# XMC4500 register map
Vendor: Infineon; File version: 1.5.3 (Reference Manual v1.5)
CPU: CM4 r2p0, little endian, MPU, FPU, 6 interrupt priority bits
Registers are 32-bit, read-write, reset 0x0 unless marked. A register's access mark holds for its fields unless they carry their own. Offsets are from the block's base; [hi:lo] are bit positions; 'fields as' and 'values as' point back to an identical list.

## SCU_OSC — System Control Unit
Base 0x50004700
0x00 OSCHPSTAT ro — OSC_HP Status Register
  [0] X1D — XTAL1 Data Value
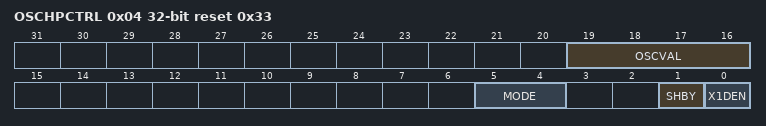
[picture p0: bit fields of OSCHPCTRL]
0x04 OSCHPCTRL reset 0x33 — OSC_HP Control Register
  [19:16] OSCVAL — OSC Frequency Value
  [5:4] MODE — Oscillator Mode
    0=External Crystal Mode and External Input Clock Mode. The oscillator Power-Saving Mode is not entered.; 1=OSC is disabled. The oscillator Power-Saving Mode is not entered.; 2=External Input Clock Mode and the oscillator Power-Saving Mode is entered; 3=OSC is disabled. The oscillator Power-Saving Mode is entered.
  [1] SHBY — Shaper Bypass
    0=The shaper is not bypassed; 1=The shaper is bypassed
  [0] X1DEN — XTAL1 Data Enable
    0=Bit X1D is not updated; 1=Bit X1D can be updated
0x0C CLKCALCONST — Clock Calibration Constant Register
  [3:0] CALIBCONST — Clock Calibration Constant Value

## SCU_TRAP — System Control Unit
Base 0x50004160
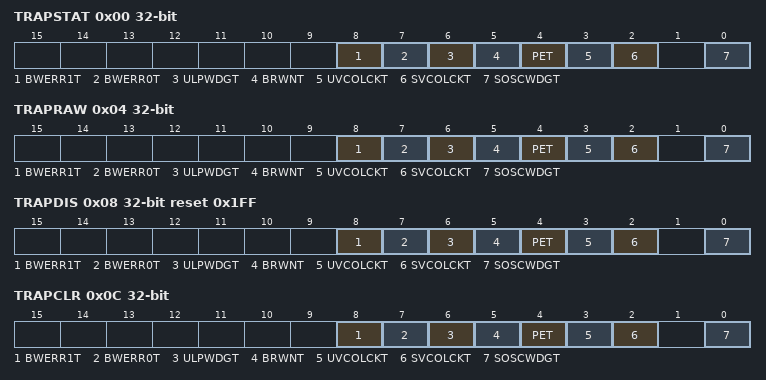
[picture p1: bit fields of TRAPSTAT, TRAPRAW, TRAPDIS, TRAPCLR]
0x00 TRAPSTAT ro — Trap Status Register
  [all] fields
    0=No pending trap request; 1=Pending trap request
  [8] BWERR1T — Peripheral Bridge 1 Trap Status
  [7] BWERR0T — Peripheral Bridge 0 Trap Status
  [6] ULPWDGT — OSC_ULP Oscillator Watchdog Trap Status
  [5] BRWNT — Brown Out Trap Status
  [4] PET — Parity Error Trap Status
  [3] UVCOLCKT — USB VCO Lock Trap Status
  [2] SVCOLCKT — System VCO Lock Trap Status
  [0] SOSCWDGT — OSC_HP Oscillator Watchdog Trap Status
0x04 TRAPRAW ro — Trap Raw Status Register
  [all] fields
    0=No pending trap request; 1=Pending trap request
  [8] BWERR1T — Peripheral Bridge 1 Trap Raw Status
  [7] BWERR0T — Peripheral Bridge 0 Trap Raw Status
  [6] ULPWDGT — OSC_ULP Oscillator Watchdog Trap Raw Status
  [5] BRWNT — Brown Out Trap Raw Status
  [4] PET — Parity Error Trap Raw Status
  [3] UVCOLCKT — USB VCO Lock Trap Raw Status
  [2] SVCOLCKT — System VCO Lock Trap Raw Status
  [0] SOSCWDGT — OSC_HP Oscillator Watchdog Trap Raw Status
0x08 TRAPDIS reset 0x1FF — Trap Disable Register
  [all] fields
    0=Trap request enabled; 1=Trap request disabled
  [8] BWERR1T — Peripheral Bridge 1 Trap Disable
  [7] BWERR0T — Peripheral Bridge 0 Trap Disable
  [6] ULPWDGT — OSC_ULP Oscillator Watchdog Trap Disable
  [5] BRWNT — Brown Out Trap Disable
  [4] PET — Parity Error Trap Disable
  [3] UVCOLCKT — USB VCO Lock Trap Disable
  [2] SVCOLCKT — System VCO Lock Trap Disable
  [0] SOSCWDGT — OSC_HP Oscillator Watchdog Trap Disable
0x0C TRAPCLR wo — Trap Clear Register
  [all] fields
    0=No effect; 1=Clear trap request
  [8] BWERR1T — Peripheral Bridge 1 Trap Clear
  [7] BWERR0T — Peripheral Bridge 0 Trap Clear
  [6] ULPWDGT — OSC_ULP Oscillator Watchdog Trap Clear
  [5] BRWNT — Brown Out Trap Clear
  [4] PET — Parity Error Trap Clear
  [3] UVCOLCKT — USB VCO Lock Trap Clear
  [2] SVCOLCKT — System VCO Lock Trap Clear
  [0] SOSCWDGT — OSC_HP Oscillator Watchdog Trap Clear
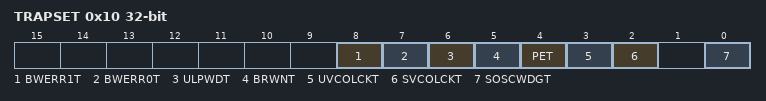
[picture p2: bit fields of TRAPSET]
0x10 TRAPSET wo
  [all] fields
    0=No effect; 1=Set trap request
  [8] BWERR1T — Peripheral Bridge 1 Trap Set
  [7] BWERR0T — Peripheral Bridge 0 Trap Set
  [6] ULPWDT — OSC_ULP Oscillator Watchdog Trap Set
  [5] BRWNT — Brown Out Trap Set
  [4] PET — Parity Error Trap Set
  [3] UVCOLCKT — USB VCO Lock Trap Set
  [2] SVCOLCKT — System VCO Lock Trap Set
  [0] SOSCWDGT — OSC_HP Oscillator Watchdog Trap Set

## SCU_HIBERNATE — System Control Unit
Base 0x50004300
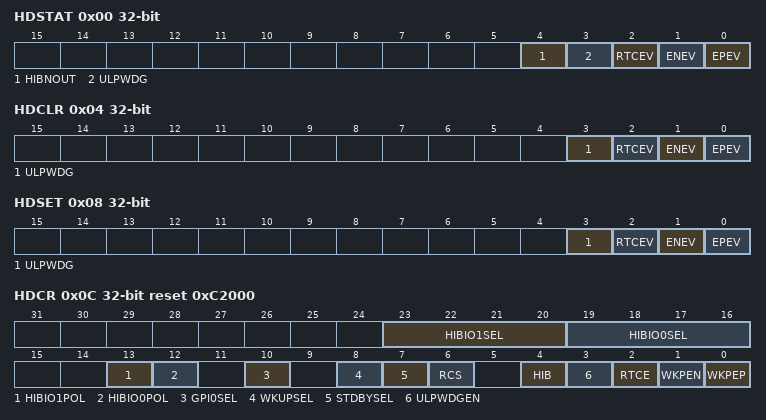
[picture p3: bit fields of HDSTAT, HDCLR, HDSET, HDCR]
0x00 HDSTAT ro — Hibernate Domain Status Register
  [4] HIBNOUT — Hibernate Control Status
    0=Hibernate not driven active to pads; 1=Hibernate driven active to pads
  [3] ULPWDG — ULP WDG Alarm Status
    0=Watchdog alarm did not occur; 1=Watchdog alarm occurred
  [2] RTCEV — RTC Event
    0=Wake-up on RTC event inactive; 1=Wake-up on RTC event active
  [1] ENEV — Wake-up Pin Event Negative Edge
    0=Wake-up on negative edge pin event inactive; 1=Wake-up on negative edge pin event active
  [0] EPEV — Wake-up Pin Event Positive Edge
    0=Wake-up on positive edge pin event inactive; 1=Wake-up on positive edge pin event active
0x04 HDCLR wo — Hibernate Domain Status Clear Register
  [3] ULPWDG — ULP WDG Alarm Clear
    0=No effect; 1=Clear watchdog alarm
  [2] RTCEV — RTC Event Clear
    0=No effect; 1=Clear wake-up event
  [1] ENEV — Wake-up Pin Event Negative Edge Clear
    0=No effect; 1=Clear wake-up event
  [0] EPEV — Wake-up Pin Event Positive Edge Clear
    0=No effect; 1=Clear wake-up event
0x08 HDSET wo — Hibernate Domain Status Set Register
  [3] ULPWDG — ULP WDG Alarm Set
    0=No effect; 1=Set watchdog alarm
  [2] RTCEV — RTC Event Set
    0=No effect; 1=Set wake-up event
  [1] ENEV — Wake-up Pin Event Negative Edge Set
    0=No effect; 1=Set wake-up event
  [0] EPEV — Wake-up Pin Event Positive Edge Set
    0=No effect; 1=Set wake-up event
0x0C HDCR reset 0xC2000 — Hibernate Domain Control Register
  [23:20] HIBIO1SEL — HIB_IO_1 Pin I/O Control (Default WKUP)
    0=Direct input, No input pull device connected; 1=Direct input, Input pull-down device connected; 2=Direct input, Input pull-up device connected; 8=Push-pull HIB Control output; 9=Push-pull WDT service output; 10=Push-pull GPIO output; 12=Open-drain HIB Control output; 13=Open-drain WDT service output; 14=Open-drain GPIO output
  [19:16] HIBIO0SEL — HIB_IO_0 Pin I/O Control (default HIBOUT)
    values as HIBIO1SEL
  [13] HIBIO1POL — HIBIO1 Polarity Set
    0=Direct value; 1=Inverted value
  [12] HIBIO0POL — HIBIO0 Polarity Set
    0=Direct value; 1=Inverted value
  [10] GPI0SEL — General Purpose Input 0 Selection
    0=HIB_IO_1 pin selected; 1=HIB_IO_0 pin selected
  [8] WKUPSEL — Wake-Up from Hibernate Trigger Input Selection
    0=HIB_IO_1 pin selected; 1=HIB_IO_0 pin selected
  [7] STDBYSEL — fSTDBY Clock Selection
    0=fOSI selected; 1=fULP selected
  [6] RCS — fRTC Clock Selection
    0=fOSI selected; 1=fULP selected
  [4] HIB — Hibernate Request Value Set
    0=External hibernate request inactive; 1=External hibernate request active
  [3] ULPWDGEN — ULP WDG Alarm Enable
    0=Wake-up event disabled; 1=Wake-up event enabled
  [2] RTCE — Wake-up on RTC Event Enable
    0=Wake-up event disabled; 1=Wake-up event enabled
  [1] WKPEN — Wake-up on Pin Event Negative Edge Enable
    0=Wake-up event disabled; 1=Wake-up event enabled
  [0] WKPEP — Wake-Up on Pin Event Positive Edge Enable
    0=Wake-up event disabled; 1=Wake-up event enabled
0x14 OSCSICTRL reset 0x1 — fOSI Control Register
  [0] PWD — Turn OFF the fOSI Clock Source
    0=Enabled; 1=Disabled
0x18 OSCULSTAT ro — OSC_ULP Status Register
  [0] X1D — XTAL1 Data Value
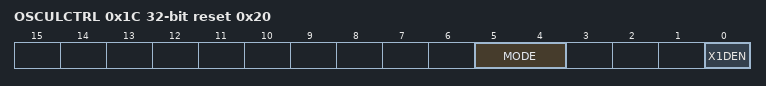
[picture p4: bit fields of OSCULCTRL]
0x1C OSCULCTRL reset 0x20 — OSC_ULP Control Register
  [5:4] MODE — Oscillator Mode
    0=Oscillator is enabled, in operation; 1=Oscillator is enabled, in bypass mode; 2=Oscillator in power down; 3=Oscillator in power down, can be used as GPI
  [0] X1DEN — XTAL1 Data General Purpose Input Enable
    0=Data input inactivated, power down; 1=Data input active

## Notices in the file
Copyright (C) 2015 Infineon Technologies AG. All rights reserved.
Infineon Technologies AG (Infineon) is supplying this software for use with
Infineon's microcontrollers.  This file can be freely distributed within
development tools that are supporting such microcontrollers.
THIS SOFTWARE IS PROVIDED "AS IS".  NO WARRANTIES, WHETHER EXPRESS, IMPLIED
OR STATUTORY, INCLUDING, BUT NOT LIMITED TO, IMPLIED WARRANTIES OF
MERCHANTABILITY AND FITNESS FOR A PARTICULAR PURPOSE APPLY TO THIS SOFTWARE.
INFINEON SHALL NOT, IN ANY CIRCUMSTANCES, BE LIABLE FOR SPECIAL, INCIDENTAL,
OR CONSEQUENTIAL DAMAGES, FOR ANY REASON WHATSOEVER.
